# ioam3358 register map
Registers are 32-bit, access not given, no defined reset value unless marked. A register's access mark holds for its fields unless they carry their own. Addresses are absolute; registers are grouped by the start of their names; [hi:lo] are bit positions; {n}, {i} and the like mark numbered series; 'fields as' and 'values as' point back to an identical list.

## EQEP1
0x48302180 EQEP1_QPOSCNT
0x48302184 EQEP1_QPOSINIT
0x48302188 EQEP1_QPOSMAX
0x4830218C EQEP1_QPOSCMP
0x48302190 EQEP1_QPOSILAT
0x48302194 EQEP1_QPOSSLAT
0x48302198 EQEP1_QPOSLAT
0x4830219C EQEP1_QUTMR
0x483021A0 EQEP1_QUPRD
0x483021A4 EQEP1_QWDTMR 16-bit
0x483021A6 EQEP1_QWDPRD 16-bit
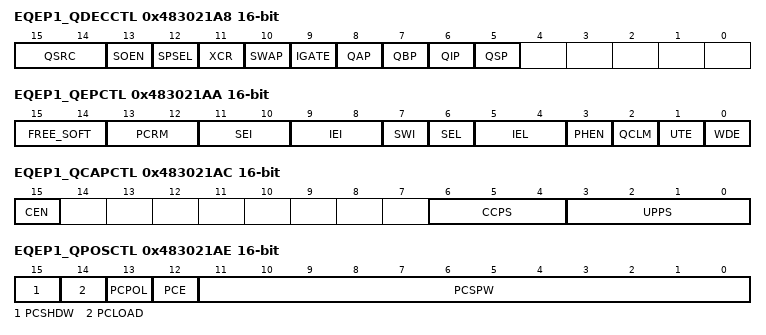
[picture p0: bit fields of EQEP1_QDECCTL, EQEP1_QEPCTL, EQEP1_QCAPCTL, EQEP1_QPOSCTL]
0x483021A8 EQEP1_QDECCTL 16-bit
  [15:14] QSRC, [13] SOEN, [12] SPSEL, [11] XCR, [10] SWAP, [9] IGATE, [8] QAP, [7] QBP, [6] QIP, [5] QSP
0x483021AA EQEP1_QEPCTL 16-bit
  [15:14] FREE_SOFT, [13:12] PCRM, [11:10] SEI, [9:8] IEI, [7] SWI, [6] SEL, [5:4] IEL, [3] PHEN, [2] QCLM, [1] UTE, [0] WDE
0x483021AC EQEP1_QCAPCTL 16-bit
  [15] CEN, [6:4] CCPS, [3:0] UPPS
0x483021AE EQEP1_QPOSCTL 16-bit
  [15] PCSHDW, [14] PCLOAD, [13] PCPOL, [12] PCE, [11:0] PCSPW
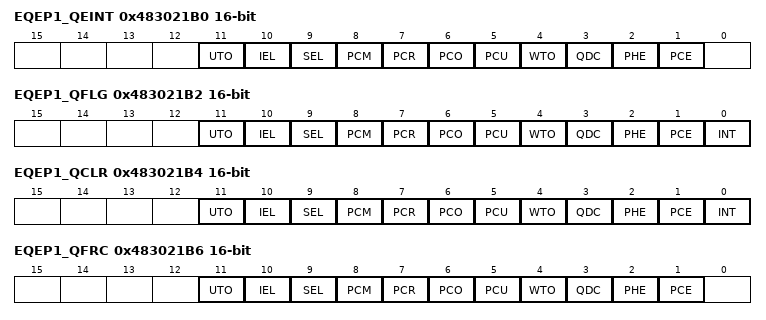
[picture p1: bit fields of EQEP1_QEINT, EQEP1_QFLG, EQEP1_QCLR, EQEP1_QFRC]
0x483021B0 EQEP1_QEINT 16-bit
  [11] UTO, [10] IEL, [9] SEL, [8] PCM, [7] PCR, [6] PCO, [5] PCU, [4] WTO, [3] QDC, [2] PHE, [1] PCE
0x483021B2 EQEP1_QFLG 16-bit
  [11] UTO, [10] IEL, [9] SEL, [8] PCM, [7] PCR, [6] PCO, [5] PCU, [4] WTO, [3] QDC, [2] PHE, [1] PCE, [0] INT
0x483021B4 EQEP1_QCLR 16-bit
  fields as EQEP1_QFLG
0x483021B6 EQEP1_QFRC 16-bit
  fields as EQEP1_QEINT
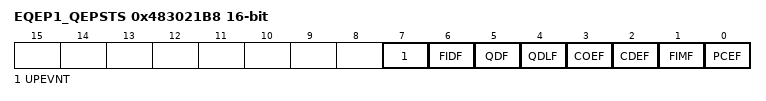
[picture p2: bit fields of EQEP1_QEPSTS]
0x483021B8 EQEP1_QEPSTS 16-bit
  [7] UPEVNT, [6] FIDF, [5] QDF, [4] QDLF, [3] COEF, [2] CDEF, [1] FIMF, [0] PCEF
0x483021BA EQEP1_QCTMR 16-bit
0x483021BC EQEP1_QCPRD 16-bit
0x483021BE EQEP1_QCTMRLAT 16-bit
0x483021C0 EQEP1_QCPRDLAT 16-bit
0x483021DC EQEP1_REVID 16-bit

## EQEP2
0x48304180 EQEP2_QPOSCNT
0x48304184 EQEP2_QPOSINIT
0x48304188 EQEP2_QPOSMAX
0x4830418C EQEP2_QPOSCMP
0x48304190 EQEP2_QPOSILAT
0x48304194 EQEP2_QPOSSLAT
0x48304198 EQEP2_QPOSLAT
0x4830419C EQEP2_QUTMR
0x483041A0 EQEP2_QUPRD
0x483041A4 EQEP2_QWDTMR 16-bit
0x483041A6 EQEP2_QWDPRD 16-bit
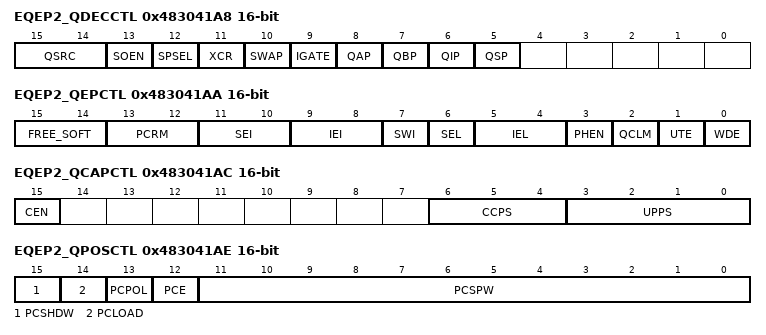
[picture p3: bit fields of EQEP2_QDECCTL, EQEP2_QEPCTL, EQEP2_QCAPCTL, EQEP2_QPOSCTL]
0x483041A8 EQEP2_QDECCTL 16-bit
  [15:14] QSRC, [13] SOEN, [12] SPSEL, [11] XCR, [10] SWAP, [9] IGATE, [8] QAP, [7] QBP, [6] QIP, [5] QSP
0x483041AA EQEP2_QEPCTL 16-bit
  [15:14] FREE_SOFT, [13:12] PCRM, [11:10] SEI, [9:8] IEI, [7] SWI, [6] SEL, [5:4] IEL, [3] PHEN, [2] QCLM, [1] UTE, [0] WDE
0x483041AC EQEP2_QCAPCTL 16-bit
  [15] CEN, [6:4] CCPS, [3:0] UPPS
0x483041AE EQEP2_QPOSCTL 16-bit
  [15] PCSHDW, [14] PCLOAD, [13] PCPOL, [12] PCE, [11:0] PCSPW
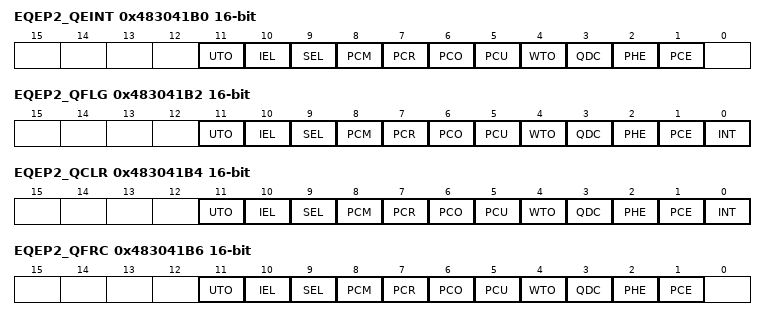
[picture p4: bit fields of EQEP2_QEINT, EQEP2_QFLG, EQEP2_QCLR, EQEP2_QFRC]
0x483041B0 EQEP2_QEINT 16-bit
  [11] UTO, [10] IEL, [9] SEL, [8] PCM, [7] PCR, [6] PCO, [5] PCU, [4] WTO, [3] QDC, [2] PHE, [1] PCE
0x483041B2 EQEP2_QFLG 16-bit
  [11] UTO, [10] IEL, [9] SEL, [8] PCM, [7] PCR, [6] PCO, [5] PCU, [4] WTO, [3] QDC, [2] PHE, [1] PCE, [0] INT
0x483041B4 EQEP2_QCLR 16-bit
  fields as EQEP2_QFLG
0x483041B6 EQEP2_QFRC 16-bit
  fields as EQEP2_QEINT
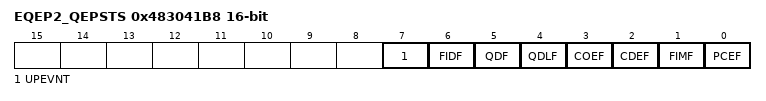
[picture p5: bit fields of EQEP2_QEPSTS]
0x483041B8 EQEP2_QEPSTS 16-bit
  [7] UPEVNT, [6] FIDF, [5] QDF, [4] QDLF, [3] COEF, [2] CDEF, [1] FIMF, [0] PCEF
0x483041BA EQEP2_QCTMR 16-bit
0x483041BC EQEP2_QCPRD 16-bit
0x483041BE EQEP2_QCTMRLAT 16-bit
0x483041C0 EQEP2_QCPRDLAT 16-bit
0x483041DC EQEP2_REVID 16-bit

## CPPI
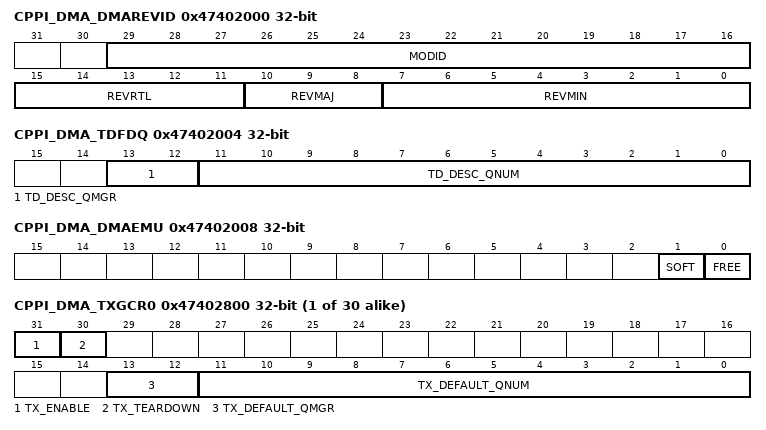
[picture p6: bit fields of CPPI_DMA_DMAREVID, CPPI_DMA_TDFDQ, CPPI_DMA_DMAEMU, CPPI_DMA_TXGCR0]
0x47402000 CPPI_DMA_DMAREVID
  [29:16] MODID, [15:11] REVRTL, [10:8] REVMAJ, [7:0] REVMIN
0x47402004 CPPI_DMA_TDFDQ
  [13:12] TD_DESC_QMGR, [11:0] TD_DESC_QNUM
0x47402008 CPPI_DMA_DMAEMU
  [1] SOFT, [0] FREE
{0x47402800+0x20*i} CPPI_DMA_TXGCR{i} (i=0..29)
  [31] TX_ENABLE, [30] TX_TEARDOWN, [13:12] TX_DEFAULT_QMGR, [11:0] TX_DEFAULT_QNUM
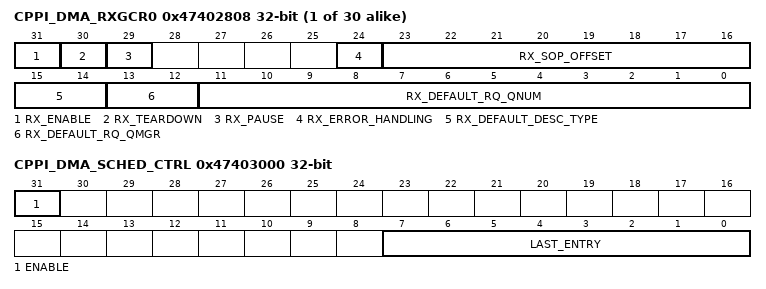
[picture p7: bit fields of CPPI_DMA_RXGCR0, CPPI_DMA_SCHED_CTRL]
{0x47402808+0x20*i} CPPI_DMA_RXGCR{i} (i=0..29)
  [31] RX_ENABLE, [30] RX_TEARDOWN, [29] RX_PAUSE, [24] RX_ERROR_HANDLING, [23:16] RX_SOP_OFFSET, [15:14] RX_DEFAULT_DESC_TYPE, [13:12] RX_DEFAULT_RQ_QMGR, [11:0] RX_DEFAULT_RQ_QNUM
{0x4740280C+0x20*i} CPPI_DMA_RXHPCRA{i} (i=0..29)
{0x47402810+0x20*i} CPPI_DMA_RXHPCRB{i} (i=0..29)
0x47403000 CPPI_DMA_SCHED_CTRL
  [31] ENABLE, [7:0] LAST_ENTRY
{0x47403800+4i} CPPI_DMA_SCHED_WORD{i} (i=0..63)

## MAILBOX
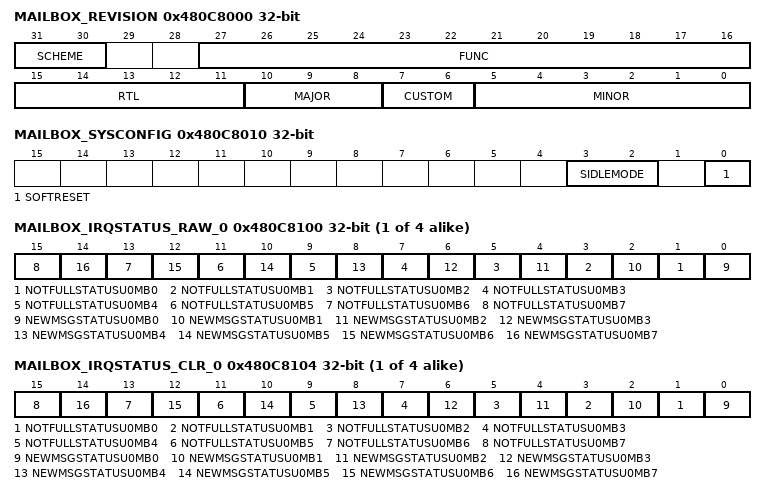
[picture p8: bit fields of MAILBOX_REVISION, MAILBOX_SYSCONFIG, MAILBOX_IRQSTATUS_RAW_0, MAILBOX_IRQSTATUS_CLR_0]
0x480C8000 MAILBOX_REVISION
  [31:30] SCHEME, [27:16] FUNC, [15:11] RTL, [10:8] MAJOR, [7:6] CUSTOM, [5:0] MINOR
0x480C8010 MAILBOX_SYSCONFIG
  [3:2] SIDLEMODE, [0] SOFTRESET
{0x480C8040+4i} MAILBOX_MESSAGE_{i} (i=0..7)
{0x480C8080+4i} MAILBOX_FIFOSTATUS_{i} (i=0..7)
  [0] FIFOFULLMBM
{0x480C80C0+4i} MAILBOX_MSGSTATUS_{i} (i=0..7)
  [2:0] NBOFMSGMBM
{0x480C8100+0x10*i} MAILBOX_IRQSTATUS_RAW_{i} (i=0..3)
  [2n+1] NOTFULLSTATUSU{i}MB{n} (n=0..7), [2n] NEWMSGSTATUSU{i}MB{n} (n=0..7)
{0x480C8104+0x10*i} MAILBOX_IRQSTATUS_CLR_{i} (i=0..3)
  fields as MAILBOX_IRQSTATUS_RAW_0
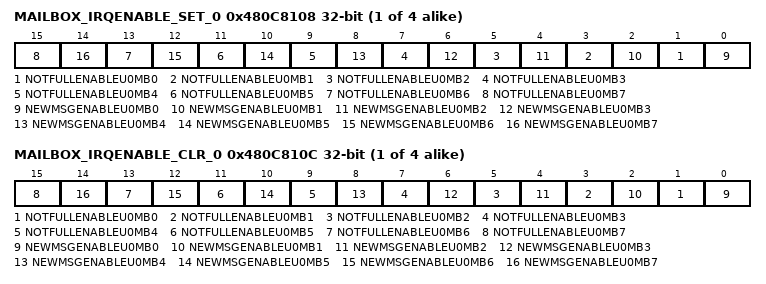
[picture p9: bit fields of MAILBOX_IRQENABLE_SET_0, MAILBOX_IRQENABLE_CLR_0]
{0x480C8108+0x10*i} MAILBOX_IRQENABLE_SET_{i} (i=0..3)
  [2n+1] NOTFULLENABLEU{i}MB{n} (n=0..7), [2n] NEWMSGENABLEU{i}MB{n} (n=0..7)
{0x480C810C+0x10*i} MAILBOX_IRQENABLE_CLR_{i} (i=0..3)
  fields as MAILBOX_IRQENABLE_SET_0
